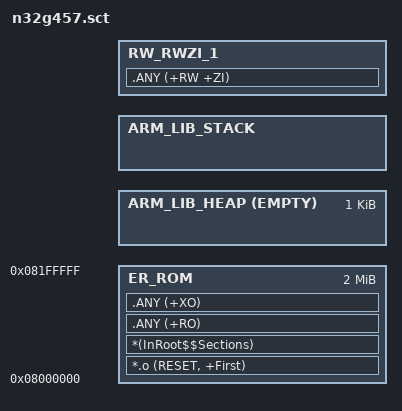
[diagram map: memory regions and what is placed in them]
#! armclang -E --target=arm-arm-none-eabi -mcpu=cortex-m4 -xc
; command above MUST be in first line (no comment above!)

;Note: Add '-mcmse' to first line if your software model is "Secure Mode".
;      #! armclang -E --target=arm-arm-none-eabi -mcpu=<CPU> -xc -mcmse


/*--------------------- Stack / Heap Configuration ---------------------------
; <h> Stack / Heap Configuration
;   <o0> Stack Size (in Bytes) <0x0-0xFFFFFFFF:8>
;   <o1> Heap Size (in Bytes) <0x0-0xFFFFFFFF:8>
;   <o2> gap before heap base (in Bytes) <0x0-0xFFFFFFFF:8>
;   <o3> gap between heap top and stack base (in Bytes) <0x0-0xFFFFFFFF:8>
;   <o4> gap between stack top and rw_zi base (in Bytes) <0x0-0xFFFFFFFF:8>
;   <o5> no init size (in Bytes) <0x0-0xFFFFFFFF:8>
; </h>
 *----------------------------------------------------------------------------*/
#define __STACK_SIZE				0x00001000
#define __HEAP_SIZE					0x00000400
#define	__GAP_INIT					0
#define __GAP_HEAP_TOP_STACK_BASE	0
#define __GAP_STACK_TOP_RW_BASE		0

#define __FLASH_BASE     			0x8000000
#define __FLASH_SIZE     			0x200000

#define __SRAM_BASE   0x20000000
#define __SRAM_SIZE   0x20000

#define __RSRAM_BASE   (__SRAM_BASE + __SRAM_SIZE)
#define __RSRAM_SIZE   0x4000

#define __SRAM_RSRAM_BASE   __SRAM_BASE
#define __SRAM_RSRAM_SIZE   (__SRAM_SIZE + __RSRAM_SIZE)

#define __RO_BASE         __FLASH_BASE
#define __RO_SIZE         __FLASH_SIZE

; Low	-> High
;|	Initial Gap	|	Heap	|	heap_stack gap	|	Stack	|	stack_rwzi gap	|	RW_ZI region |
#define __HEAP_BASE			(AlignExpr(__SRAM_RSRAM_BASE + __GAP_INIT, 8))
#define __HEAP_TOP			(AlignExpr(__HEAP_BASE + __HEAP_SIZE, 8))
#define __STACK_TOP			(AlignExpr(__HEAP_TOP + __GAP_HEAP_TOP_STACK_BASE + __STACK_SIZE, 8))
#define __RWZI_BASE_1			(AlignExpr(__GAP_STACK_TOP_RW_BASE + __STACK_TOP, 8))

#define __RWZI_SIZE_1			(AlignExpr(__SRAM_RSRAM_SIZE - __GAP_INIT - __HEAP_SIZE - __GAP_HEAP_TOP_STACK_BASE - __STACK_SIZE - __GAP_STACK_TOP_RW_BASE, 8))

/*----------------------------------------------------------------------------
  Scatter Region definition
 *----------------------------------------------------------------------------*/
LR_ROM __RO_BASE __RO_SIZE  {                         ; load region size_region
    ER_ROM __RO_BASE __RO_SIZE  {                     ; load address = execution address
        *.o (RESET, +First)
        *(InRoot$$Sections)
        .ANY (+RO)
        .ANY (+XO)
    }

    ARM_LIB_HEAP  __HEAP_BASE EMPTY  __HEAP_SIZE  {   ; Reserve empty region for heap
    }

    ARM_LIB_STACK __STACK_TOP EMPTY - __STACK_SIZE {  ; Reserve empty region for stack
    }
	
	RW_RWZI_1 __RWZI_BASE_1 (__RWZI_SIZE_1)  {
		.ANY (+RW +ZI)
	}	
}
